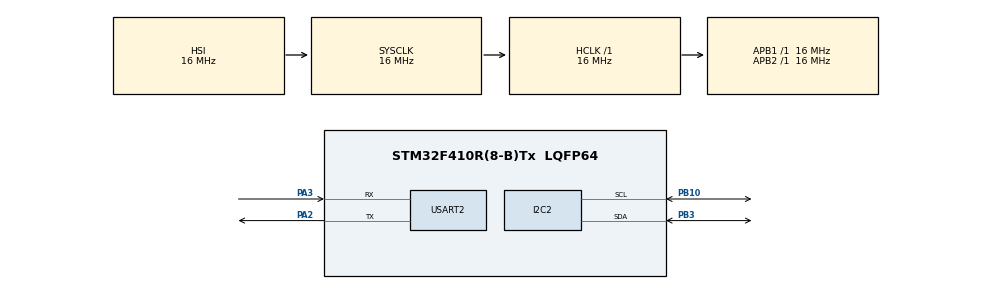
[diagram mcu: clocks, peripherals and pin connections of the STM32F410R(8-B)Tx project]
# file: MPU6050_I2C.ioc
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Mcu.Family=STM32F4
Mcu.Name=STM32F410R(8-B)Tx
Mcu.Package=LQFP64
NVIC.PriorityGroup=NVIC_PRIORITYGROUP_4
PA13.Mode=Serial_Wire
PA13.Signal=SYS_JTMS-SWDIO
PA14.Mode=Serial_Wire
PA14.Signal=SYS_JTCK-SWCLK
PA2.Mode=Asynchronous
PA2.Signal=USART2_TX
PA3.Mode=Asynchronous
PA3.Signal=USART2_RX
PB10.Mode=I2C
PB10.Signal=I2C2_SCL
PB3.Mode=I2C
PB3.Signal=I2C2_SDA
ProjectManager.HeapSize=0x200
ProjectManager.StackSize=0x400
ProjectManager.TargetToolchain=STM32CubeIDE
RCC.AHBFreq_Value=16000000
RCC.APB1Freq_Value=16000000
RCC.APB2Freq_Value=16000000
RCC.CortexFreq_Value=16000000
RCC.HSE_VALUE=25000000
RCC.HSI_VALUE=16000000
RCC.LSE_VALUE=32768
RCC.SYSCLKFreq_VALUE=16000000
RCC.VCOOutputFreq_Value=192000000
USART2.VirtualMode=VM_ASYNC
board=custom

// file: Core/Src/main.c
/* USER CODE BEGIN Header */
/**
  ******************************************************************************
  * @file           : main.c
  * @brief          : Main program body
  ******************************************************************************
  * @attention
  *
  * Copyright (c) 2022 STMicroelectronics.
  * All rights reserved.
  *
  * This software is licensed under terms that can be found in the LICENSE file
  * in the root directory of this software component.
  * If no LICENSE file comes with this software, it is provided AS-IS.
  *
  ******************************************************************************
  */
/* USER CODE END Header */
#include "main.h"
#include "i2c.h"
#include "usart.h"
#include "gpio.h"

/* USER CODE BEGIN Includes */
#include "MPU-60X0.h"
/* USER CODE END Includes */

/* USER CODE BEGIN PD */
#define SLAVE_ADDRESS 0x0068 // change this according to ur setup
/* USER CODE END PD */

void SystemClock_Config(void);

/* USER CODE BEGIN 0 */

int __io_putchar(int ch)
{
  if (ch == '\n') {
    __io_putchar('\r');
  }

  HAL_UART_Transmit(&huart2, (uint8_t*)&ch, 1, HAL_MAX_DELAY);

  return 1;
}

/* USER CODE END 0 */

int main(void)
{

  /* MCU Configuration--------------------------------------------------------*/

  /* Reset of all peripherals, Initializes the Flash interface and the Systick. */
  HAL_Init();

  /* Configure the system clock */
  SystemClock_Config();

  /* Initialize all configured peripherals */
  MX_GPIO_Init();
  MX_I2C2_Init();
  MX_USART2_UART_Init();
  /* USER CODE BEGIN 2 */

  MPU60X0_Init(SLAVE_ADDRESS, &hi2c2);
  MPU60X0_DLPF(SLAVE_ADDRESS, &hi2c2, 4);

  /* USER CODE END 2 */

  /* Infinite loop */
  /* USER CODE BEGIN WHILE */
  while (1)
  {
	  printf("X: %d, Y: %d\n",MPU60X0_GyroReceive(SLAVE_ADDRESS, &hi2c2, 'X'),MPU60X0_GyroReceive(SLAVE_ADDRESS, &hi2c2, 'y'));

    /* USER CODE END WHILE */

  }
}

void SystemClock_Config(void)
{
  RCC_OscInitTypeDef RCC_OscInitStruct = {0};
  RCC_ClkInitTypeDef RCC_ClkInitStruct = {0};

  /** Configure the main internal regulator output voltage
  */
  __HAL_RCC_PWR_CLK_ENABLE();
  __HAL_PWR_VOLTAGESCALING_CONFIG(PWR_REGULATOR_VOLTAGE_SCALE1);

  /** Initializes the RCC Oscillators according to the specified parameters
  * in the RCC_OscInitTypeDef structure.
  */
  RCC_OscInitStruct.OscillatorType = RCC_OSCILLATORTYPE_HSI;
  RCC_OscInitStruct.HSIState = RCC_HSI_ON;
  RCC_OscInitStruct.HSICalibrationValue = RCC_HSICALIBRATION_DEFAULT;
  RCC_OscInitStruct.PLL.PLLState = RCC_PLL_NONE;
  if (HAL_RCC_OscConfig(&RCC_OscInitStruct) != HAL_OK)
  {
    Error_Handler();
  }

  /** Initializes the CPU, AHB and APB buses clocks
  */
  RCC_ClkInitStruct.ClockType = RCC_CLOCKTYPE_HCLK|RCC_CLOCKTYPE_SYSCLK
                              |RCC_CLOCKTYPE_PCLK1|RCC_CLOCKTYPE_PCLK2;
  RCC_ClkInitStruct.SYSCLKSource = RCC_SYSCLKSOURCE_HSI;
  RCC_ClkInitStruct.AHBCLKDivider = RCC_SYSCLK_DIV1;
  RCC_ClkInitStruct.APB1CLKDivider = RCC_HCLK_DIV1;
  RCC_ClkInitStruct.APB2CLKDivider = RCC_HCLK_DIV1;

  if (HAL_RCC_ClockConfig(&RCC_ClkInitStruct, FLASH_LATENCY_0) != HAL_OK)
  {
    Error_Handler();
  }
}

void Error_Handler(void)
{
  __disable_irq();
  while (1)
  {
  }
}
